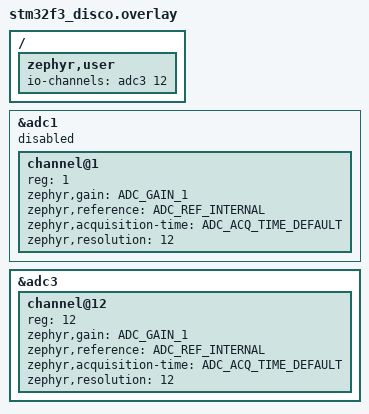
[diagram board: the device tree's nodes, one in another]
/*
 * Copyright (c) 2023 STMicroelectronics
 *
 * SPDX-License-Identifier: Apache-2.0
 */

 / {
	zephyr,user {
		/* adjust channel number according to pinmux in board.dts */
		io-channels = <&adc3 12>;
	};
};

&adc1 {
	#address-cells = <1>;
	#size-cells = <0>;

	status = "disabled";

	channel@1 {
		reg = <1>;
		zephyr,gain = "ADC_GAIN_1";
		zephyr,reference = "ADC_REF_INTERNAL";
		zephyr,acquisition-time = <ADC_ACQ_TIME_DEFAULT>;
		zephyr,resolution = <12>;
	};
};

&adc3 {
	#address-cells = <1>;
	#size-cells = <0>;

	channel@12 {
		reg = <12>;
		zephyr,gain = "ADC_GAIN_1";
		zephyr,reference = "ADC_REF_INTERNAL";
		zephyr,acquisition-time = <ADC_ACQ_TIME_DEFAULT>;
		zephyr,resolution = <12>;
	};
};
